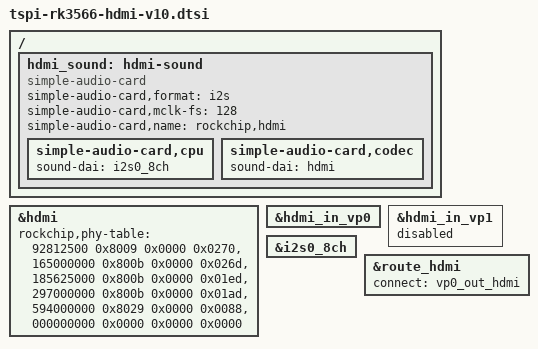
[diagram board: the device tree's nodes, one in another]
/********************************************************************
 * 共建开源生态是我们的目标。为此我们努力把性价比和颜值做到极致。
 * 同时全面开放SDK、原理图、PCB等所有软硬件资料。
 * 提供交流平台、免费训练营、开发者扶持计划等，让您能够尽情发挥您的才华。
 * 我们坚信自由和定制化是开源生态的核心。
 * 泰山派开发板不仅仅是立创开发板的产品，它更是我们共同努力的成果。
 * 我们只是抛砖引玉，期望能够激发出更多的创意和想法。
 * 我们渴望与志同道合的伙伴们携手合作，共同探索无限可能。
 * 让我们各展所长，共同建设一个强大的开源生态系统。
 * 泰山派开发板等待着您的加入。
 * 让我们一起推动技术的前进，一起创未来！
 *********************************************************************
 * 立创开发板不靠卖板赚钱，以培养中国工程师为己任。  
 * 开发板官网：www.lckfb.com
 * 嘉立创论坛：www.jlc-bbs.com/lckfb 
 * 资料教程：wiki.lckfb.com  
 * 开源项目：https://oshwhub.com/search?wd=%E6%B3%B0%E5%B1%B1%E6%B4%BE   
 * 关注B站：【立创开发板】，掌握我们的最新动态！  
 *********************************************************************/
 
/{
    hdmi_sound: hdmi-sound {
		compatible = "simple-audio-card";
		simple-audio-card,format = "i2s";
		simple-audio-card,mclk-fs = <128>;
		simple-audio-card,name = "rockchip,hdmi";
		status = "disabled";

		simple-audio-card,cpu {
				sound-dai = <&i2s0_8ch>;
		};
		simple-audio-card,codec {
				sound-dai = <&hdmi>;
		};
	};
};

&hdmi {
	status = "okay";
	rockchip,phy-table =
		<92812500  0x8009 0x0000 0x0270>,
		<165000000 0x800b 0x0000 0x026d>,
		<185625000 0x800b 0x0000 0x01ed>,
		<297000000 0x800b 0x0000 0x01ad>,
		<594000000 0x8029 0x0000 0x0088>,
		<000000000 0x0000 0x0000 0x0000>;
};

&hdmi_in_vp0 {
	status = "okay";
};

&hdmi_in_vp1 {
	status = "disabled";
};

&hdmi_sound {
	status = "okay";
};

&i2s0_8ch {
	status = "okay";
};

&route_hdmi {
	status = "okay";
	connect = <&vp0_out_hdmi>;
};
